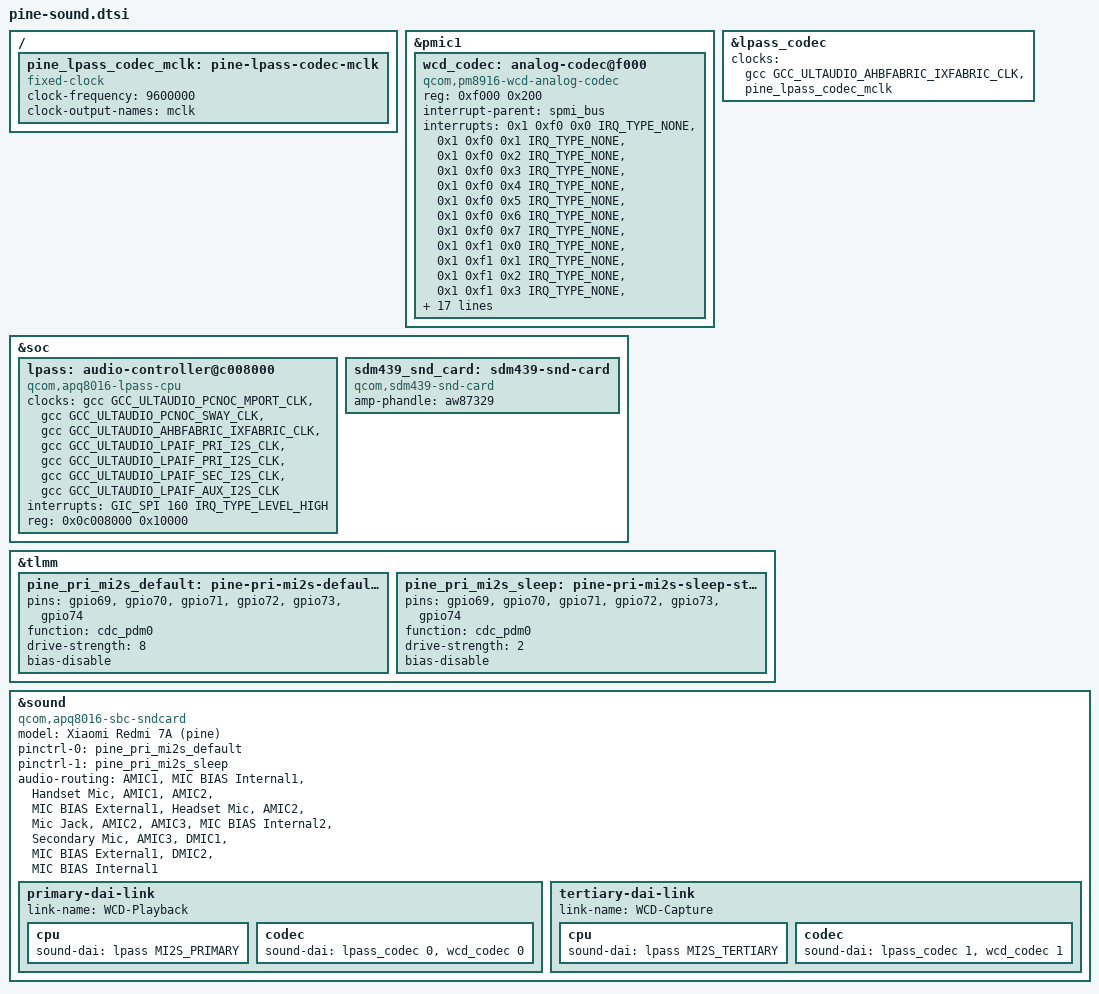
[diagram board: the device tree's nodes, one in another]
/*
 * Edited by: grayfox951 <admin@dnr.qzz.io>
 *
 * SPDX-License-Identifier: BSD-2-Clause
 */

// SPDX-License-Identifier: BSD-3-Clause
/*
 * Sound card for Xiaomi Redmi 7A (pine) / SDM439
 * =================================================
 * Kernel: msm89x7-mainline/linux @ msm89x7/7.1.3
 *
 * Machine driver:  sound/soc/qcom/apq8016_sbc.c
 *                    compatible = "qcom,apq8016-sbc-sndcard"
 *                  NO variant of it is needed. See snd/sdm439-snd-card.c.
 *
 * Codecs used:
 *                  &wcd_codec     qcom,pm8916-wcd-analog-codec  @ SPMI 0xf000
 *                                sound/soc/codecs/msm8916-wcd-analog.c
 *                                (PM8953 WCD analog half)
 *                  &lpass_codec   qcom,msm8916-wcd-digital-codec @ 0x0c0f0000
 *                                sound/soc/codecs/msm8916-wcd-digital.c
 *                                (WCD digital half + the real DMIC1/DMIC2 decoder)
 *   CPU DAI:        &lpass         qcom,apq8016-lpass-cpu
 *                                sound/soc/qcom/lpass-apq8016.c + lpass-cpu.c
 *
 * ---------------------------------------------------------------------------
 * EVERY LABEL AND PROPERTY BELOW WAS GREP-VERIFIED IN
 *   fk/arch/arm64/boot/dts/qcom/
 * unless it is inside a block explicitly marked TODO.  See snd/README.md for
 * the exact commands.
 *
 * Pine's include chain is
 *   sdm439-xiaomi-pine.dts -> sdm439.dtsi -> msm8937.dtsi
 *                          -> pm8953.dtsi, pmi632.dtsi
 * msm8937.dtsi does NOT include msm8916.dtsi.  So none of the msm8916.dtsi
 * labels (lpass:, lpass_codec:, sound:) exist for this board; the msm8937
 * equivalents are used, and &lpass is created here.
 * ---------------------------------------------------------------------------
 */

#include <dt-bindings/clock/qcom,gcc-sdm439.h>
#include <dt-bindings/interrupt-controller/arm-gic.h>
#include <dt-bindings/interrupt-controller/irq.h>
#include <dt-bindings/sound/qcom,lpass.h>

/* =========================================================================
 * 1. MCLK placeholder for lpass_codec
 *
 * msm8916-wcd-digital.c requires two clocks by name:
 *     "ahbix-clk"  and  "mclk"   (verified: get_clks(), devm_clk_get())
 * and then does clk_prepare_enable() on both, so probe FAILS without them.
 *
 *   ahbix-clk -> &gcc GCC_ULTAUDIO_AHBFABRIC_IXFABRIC_CLK
 *        Token verified in fk/include/dt-bindings/clock/qcom,gcc-sdm439.h:21
 *        Gate  verified in fk/drivers/clk/qcom/gcc-sdm439.c:3499
 *
 *   mclk      -> NO PROVIDER EXISTS.  TODO (blocking, for the clock agent).
 *        GCC_CODEC_DIGCODEC_CLK is NOT in qcom,gcc-sdm439.h (the ULTAUDIO
 *        block stops at index 158) and gcc-sdm439.c contains no digcodec
 *        gate at all.  On msm8916 this is GCC_CODEC_DIGCODEC_CLK = 159
 *        (qcom,gcc-msm8916.h:168) - one past the end of the sdm439 block.
 *        The fixed-clock below is a PLACEHOLDER so lpass_codec can probe and
 *        so the rest of the card can be brought up.  It is correct only
 *        because this board only ever runs the WCD digital codec at 9600000
 *        (apq8016_sbc.c DEFAULT_MCLK_RATE = 9600000, the only value ever
 *        passed to snd_soc_component_set_sysclk()).  If a different rate is
 *        ever needed, clk_set_rate() on a fixed clock returns -EINVAL and
 *        msm8916_wcd_digital_component_set_sysclk() propagates it.
 *
 *        REQUIRED FROM THE CLOCK AGENT: a real, gateable, settable 9.6 MHz
 *        root for the WCD CDC block, exported either as a new
 *        GCC_CODEC_DIGCODEC_CLK token in qcom,gcc-sdm439.h plus a gate in
 *        gcc-sdm439.c, or as a separate clock driver.  When it lands,
 *        replace &pine_lpass_codec_mclk below with that phandle.
 *
 *        ALSO REQUIRED: gcc-sdm439.o is NOT in drivers/clk/qcom/Makefile
 *        (only gcc-msm8917.o is, line 69).  gcc-msm8917.c matches
 *        "qcom,gcc-sdm439" at line 4179 but its table has zero ULTAUDIO
 *        gates, so even ahbix-clk above is dead until that Makefile line is
 *        added.  See snd/README.md.
 * ======================================================================= */

/ {
	pine_lpass_codec_mclk: pine-lpass-codec-mclk {
		compatible = "fixed-clock";
		#clock-cells = <0>;
		clock-frequency = <9600000>;
		clock-output-names = "mclk";
	};
};

/* =========================================================================
 * 2. WCD analog codec - PM8953 @ SPMI 0xf000, inside pmic@1
 *
 * Placed in &pmic1 (label verified: fk/arch/arm64/boot/dts/qcom/pm8953.dtsi:122).
 * pm8953.dtsi does NOT include pm8937.dtsi, so the wcd_codec node that exists
 * in pm8937.dtsi:158 is NOT visible to pine.  It is defined here instead,
 * byte-compatible with that one except for the supply names (see below).
 *
 * pmic1 already carries "#address-cells = <1>; #size-cells = <0>;" so
 * reg = <0xf000 0x200> is reg=0xf000 size=0x200.  Do not add address/size
 * cells here - pm8937.dtsi's copy does not have them either.
 *
 * ---- SUPPLY NAMES: THE ONE PLACE THIS FILE DEVIATES FROM STOCK DT -------
 *
 * stock sdm439-audio.dtsi uses the CAF names:
 *      cdc-vdd-io-supply      cdc-vdda-cp-supply
 *      cdc-vdd-pa-supply      cdc-vdd-mic-bias-supply
 *
 * sound/soc/codecs/msm8916-wcd-analog.c does NOT read any of those.  Its
 * only regulator request is (verified, exact source):
 *      static const char * const supply_names[] = {
 *              "vdd-cdc-io",
 *              "vdd-cdc-tx-rx-cx",
 *      };
 *      ret = devm_regulator_bulk_get(dev, ARRAY_SIZE(priv->supplies),
 *                                      priv->supplies);
 *      if (ret) { dev_err(...); return ret; }        <- probe dies here
 *
 * devm_regulator_bulk_get() looks up "<supply_name>-supply", i.e.
 * vdd-cdc-io-supply and vdd-cdc-tx-rx-cx-supply.  A node carrying only the
 * CAF names fails probe with -EPROBE_DEFER/-EINVAL.
 *
 * The mainline spelling is taken from the closest sibling that already works
 * in this kernel, fk/arch/arm64/boot/dts/qcom/msm8917-xiaomi-wingtech.dtsi:537
 * (msm8937 + pm8937 + the same codec driver):
 *      vdd-cdc-io-supply       = <&pm8937_l5>;
 *      vdd-cdc-tx-rx-cx-supply = <&pm8937_s4>;
 *
 * Rail mapping for pine (labels verified in sdm439-xiaomi-pine.dts):
 *      pm8953_l5  1.80 V fixed      -> vdd-cdc-io
 *      pm8953_s4  1.90 - 2.04 V    -> vdd-cdc-tx-rx-cx   (stock: cdc-vdda-cp)
 *      pm8953_s4  1.90 - 2.04 V    -> stock "cdc-vdd-pa" (no consumer below)
 *      pm8953_l13 3.05 - 3.10 V    -> vdd-micbias         (stock: cdc-vdd-mic-bias)
 *
 * The CAF-named properties are kept underneath, commented as what they are,
 * so the rail intent is recorded and so a downstream/CAF driver reading them
 * finds the right phandle.  The mainline driver ignores them.
 *
 * ---- NO clocks= ON THIS NODE -------------------------------------------
 * pm8937.dtsi:158 hangs this node off &q6afecc, whose compatible is
 * "qcom,q6afe-clocks".  No driver in this kernel binds that string, so the
 * node would sit in deferred probe forever.  It does not have to: grep shows
 * msm8916-wcd-analog.c contains no devm_clk_get()/clk_get() at all - it never
 * touches a clock, so no clocks property is needed and none is supplied.
 *
 * ---- INTERRUPT NAMES ---------------------------------------------------
 * Three of the fourteen names below differ from stock, and they are the ones
 * the driver actually looks up by name (verified in the probe function):
 *
 *   stock "mbhc_int"      -> "mbhc_switch_int"
 *   stock "but_press_det" -> "mbhc_but_press_det"
 *   stock "but_rel_det"   -> "mbhc_but_rel_det"
 *
 * because probe does:
 *      irq = platform_get_irq_byname(pdev, "mbhc_switch_int");
 *      if (irq < 0) return irq;                       <- no fallback
 *      ...
 *      if (priv->mbhc_btn_enabled) {
 *              irq = platform_get_irq_byname(pdev, "mbhc_but_press_det");
 *              if (irq < 0) return irq;
 *              irq = platform_get_irq_byname(pdev, "mbhc_but_rel_det");
 *              if (irq < 0) return irq;
 *      }
 *
 * mbhc_btn_enabled is true only if BOTH qcom,mbhc-vthreshold-low and
 * qcom,mbhc-vthreshold-high are present arrays of 5 values; those are
 * supplied below so button detection stays on and the two button IRQs are
 * required.
 * The other eleven names are only labels (platform_get_irq() is positional);
 * they are kept byte-identical to stock.
 * ======================================================================= */

&pmic1 {
	status = "okay";

	wcd_codec: analog-codec@f000 {
		compatible = "qcom,pm8916-wcd-analog-codec";
		reg = <0xf000 0x200>;
		reg-names = "pmic-codec-core";
		#sound-dai-cells = <1>;

		interrupt-parent = <&spmi_bus>;
		interrupts = <0x1 0xf0 0x0 IRQ_TYPE_NONE>,
			     <0x1 0xf0 0x1 IRQ_TYPE_NONE>,
			     <0x1 0xf0 0x2 IRQ_TYPE_NONE>,
			     <0x1 0xf0 0x3 IRQ_TYPE_NONE>,
			     <0x1 0xf0 0x4 IRQ_TYPE_NONE>,
			     <0x1 0xf0 0x5 IRQ_TYPE_NONE>,
			     <0x1 0xf0 0x6 IRQ_TYPE_NONE>,
			     <0x1 0xf0 0x7 IRQ_TYPE_NONE>,
			     <0x1 0xf1 0x0 IRQ_TYPE_NONE>,
			     <0x1 0xf1 0x1 IRQ_TYPE_NONE>,
			     <0x1 0xf1 0x2 IRQ_TYPE_NONE>,
			     <0x1 0xf1 0x3 IRQ_TYPE_NONE>,
			     <0x1 0xf1 0x4 IRQ_TYPE_NONE>,
			     <0x1 0xf1 0x5 IRQ_TYPE_NONE>;
		interrupt-names = "spk_cnp_int",
				  "spk_clip_int",
				  "spk_ocp_int",
				  "ins_rem_det1",
				  "but_rel_det",
				  "but_press_det",
				  "ins_rem_det",
				  "mbhc_switch_int",
				  "ear_ocp_int",
				  "hphr_ocp_int",
				  "hphl_ocp_det",
				  "ear_cnp_int",
				  "hphr_cnp_int",
				  "hphl_cnp_int";

		/* ---- supplies the mainline driver actually consumes ---- */
		vdd-cdc-io-supply       = <&pm8953_l5>;   /* 1.80 V  (CDC_VDD_IO)  */
		vdd-cdc-tx-rx-cx-supply = <&pm8953_s4>;   /* 1.90-2.04 V (CDC_VDDA_CP) */
		vdd-micbias-supply      = <&pm8953_l13>;  /* 3.05-3.10 V (CDC_VDD_MIC_BIAS) */

		/* ---- stock/CAF spellings: recorded, not consumed ---- */
		cdc-vdd-io-supply       = <&pm8953_l5>;
		qcom,cdc-vdd-io-voltage  = <1800000 1800000>;
		cdc-vdda-cp-supply      = <&pm8953_s4>;
		qcom,cdc-vdda-cp-voltage = <1900000 2050000>;
		cdc-vdd-pa-supply       = <&pm8953_s4>;
		qcom,cdc-vdd-pa-voltage = <1900000 2050000>;
		cdc-vdd-mic-bias-supply = <&pm8953_l13>;
		qcom,cdc-vdd-mic-bias-voltage = <3075000 3075000>;
		qcom,cdc-mclk-clk-rate  = <9600000>;

		/* ---- MBHC ----
		 * Both threshold arrays must be present and 5 entries long or
		 * mbhc_btn_enabled goes false and the button IRQs are dropped.
		 * Values are the msm8916 reference set; pine-specific threshold
		 * tuning is TODO (measure against a real headset).
		 */
		qcom,mbhc-vthreshold-low  = <75 150 237 450 500>;
		qcom,mbhc-vthreshold-high = <75 150 237 450 500>;
		qcom,micbias1-ext-cap;

		status = "okay";
	};
};

/* =========================================================================
 * 3. LPASS CPU DAI
 *
 * There is NO lpass node anywhere on pine's include chain: msm8937.dtsi has
 * none, and the only lpass node in the fork is msm8916.dtsi:2125, which pine
 * never includes.  So it is created here.
 *
 * ADDRESS - UNVERIFIED, TODO.
 * msm8916 puts LPAIF at AON_base + 0x8000, with its sound iomux at
 * AON_base + 0x2000.  sdm439's AON_base is 0x0c000000 but its internal
 * offsets clearly differ: the sound iomux is at AON+0x51000, not AON+0x2000,
 * and the WCD digital block is at AON+0xf0000, not AON+0x1c000.  So
 * "AON_base + 0x8000" is a hypothesis, not a derived fact.  It is marked as
 * such and must be confirmed before audio can work - see snd/README.md for
 * a safe read-only test procedure.  A wrong base here cannot damage the
 * device: lpass-cpu only reads its AHBIX config register and the DMAs.
 * 0x0c008000 is used below as the hypothesis.
 *
 * NO qcom,adsp PHANDLE.  asoc_qcom_lpass_cpu_platform_probe() does
 *      dsp_of_node = of_parse_phandle(pdev->dev.of_node, "qcom,adsp", 0);
 *      if (dsp_of_node) { dev_err(dev, "DSP exists and holds audio
 *      resources\n"); return -EBUSY; }
 * so a qcom,adsp phandle here is an unconditional probe failure.  pine's
 * stock DTB is stock-derived and does contain one; it is simply not written
 * here.
 *
 * CLOCKS.  clock-names is positional and must match the order the driver
 * asks for.  All seven tokens below were grep-verified in
 * fk/include/dt-bindings/clock/qcom,gcc-sdm439.h and every gate is implemented
 * in fk/drivers/clk/qcom/gcc-sdm439.c (the two tables agree 1:1).
 *
 *   name             token                                    hdr line
 *   ---------------  --------------------------------------   --------
 *   pcnoc-mport-clk  GCC_ULTAUDIO_PCNOC_MPORT_CLK            sdm439.h:17
 *   pcnoc-sway-clk   GCC_ULTAUDIO_PCNOC_SWAY_CLK             sdm439.h:18
 *   ahbix-clk        GCC_ULTAUDIO_AHBFABRIC_IXFABRIC_CLK     sdm439.h:21
 *   mi2s-bit-clk0    GCC_ULTAUDIO_LPAIF_PRI_I2S_CLK          sdm439.h:23
 *   mi2s-bit-clk1    GCC_ULTAUDIO_LPAIF_PRI_I2S_CLK          sdm439.h:23
 *   mi2s-bit-clk2    GCC_ULTAUDIO_LPAIF_SEC_I2S_CLK          sdm439.h:24
 *   mi2s-bit-clk3    GCC_ULTAUDIO_LPAIF_AUX_I2S_CLK          sdm439.h:25
 *
 * mi2s-bit-clk0 and mi2s-bit-clk1 deliberately share PRI_I2S_CLK; that is
 * what msm8916.dtsi:2136-2137 does and it is not a typo.
 *
 * mi2s-osr-clk0..3 are NOT listed: lpass-cpu.c:1224 gets them with
 * devm_clk_get_optional(), so they are genuinely optional and are left out.
 *
 * BLOCKING: none of these clocks resolve until gcc-sdm439.o is added to
 * drivers/clk/qcom/Makefile.  See the note at the top of this file.
 * ======================================================================= */

&soc {
	lpass: audio-controller@c008000 {
		status = "okay";

		/* both spellings are accepted by lpass-apq8016.c */
		compatible = "qcom,apq8016-lpass-cpu", "qcom,lpass-cpu-apq8016";

		clocks = <&gcc GCC_ULTAUDIO_PCNOC_MPORT_CLK>,
			 <&gcc GCC_ULTAUDIO_PCNOC_SWAY_CLK>,
			 <&gcc GCC_ULTAUDIO_AHBFABRIC_IXFABRIC_CLK>,
			 <&gcc GCC_ULTAUDIO_LPAIF_PRI_I2S_CLK>,
			 <&gcc GCC_ULTAUDIO_LPAIF_PRI_I2S_CLK>,
			 <&gcc GCC_ULTAUDIO_LPAIF_SEC_I2S_CLK>,
			 <&gcc GCC_ULTAUDIO_LPAIF_AUX_I2S_CLK>;
		clock-names = "pcnoc-mport-clk",
			      "pcnoc-sway-clk",
			      "ahbix-clk",
			      "mi2s-bit-clk0",
			      "mi2s-bit-clk1",
			      "mi2s-bit-clk2",
			      "mi2s-bit-clk3";

		/* TODO: verify both against the stock sdm439 device tree. */
		interrupts = <GIC_SPI 160 IRQ_TYPE_LEVEL_HIGH>;
		interrupt-names = "lpass-irq-lpaif";

		/* TODO: unverified base, see the note above. */
		reg = <0x0c008000 0x10000>;
		reg-names = "lpass-lpaif";

		#sound-dai-cells = <1>;
		#address-cells = <1>;
		#size-cells = <0>;
	};
};

/* =========================================================================
 * 4. WCD digital codec (lpass_codec)
 *
 * Label verified: fk/arch/arm64/boot/dts/qcom/msm8937.dtsi:2353,
 * reg = <0x0c0f0000 0x400>, compatible qcom,msm8916-wcd-digital-codec.
 * That is the address the stock sdm439-audio.dtsi also uses for
 * "msm_digital_codec", so it needs no guessing.
 *
 * Its stock clocks come from &q6afecc (compatible "qcom,q6afe-clocks"), for
 * which this kernel has NO driver, and the second clock is
 * &rpmcc RPM_SMD_XO_CLK_SRC - a 19.2 MHz fixed root that clk_set_rate() to
 * 9600000 (what msm8916_wcd_digital_component_set_sysclk() does) would
 * reject.  Both are replaced below.
 * ======================================================================= */

&lpass_codec {
	clocks = <&gcc GCC_ULTAUDIO_AHBFABRIC_IXFABRIC_CLK>,
		 <&pine_lpass_codec_mclk>;
	clock-names = "ahbix-clk", "mclk";

	/*
	 * TODO(clock agent): drop &pine_lpass_codec_mclk for the real
	 * GCC_CODEC_DIGCODEC_CLK-equivalent once it exists.
	 */
	#sound-dai-cells = <1>;

	status = "okay";
};

/* =========================================================================
 * 5. TLMM audio pinmux
 *
 * pine's chain has NO audio pinctrl labels of its own - msm8937.dtsi's tlmm
 * defines only blsp/cci/cam_mclk/wcss states.  So the states are declared
 * here.
 *
 * The playback (Primary MI2S) group below is copied from the in-tree
 * msm8937 board dtsi (fk/arch/arm64/boot/dts/qcom/msm8937-qdsp6.dtsi:80-100),
 * so the pin numbers gpio69..74 and the function string "cdc_pdm0" are both
 * verified for the qcom,msm8917-pinctrl node at msm8937.dtsi:820.
 *
 * TODO: confirm that pine actually bonds Primary MI2S to gpio69..74.  The
 * stock CAF DT routes it through a "msm_cdc_pinctrl_pri" node whose pinctrl-0
 * is the pair cdc_pdm_lines_act + cdc_pdm_lines_2_act, i.e. TWELVE cdc_pdm0
 * pins, not six.  Whether pine uses the 69-74 group, the 63-68 group, or
 * both has not been confirmed from any file available locally.
 *
 * TODO: the digital microphone needs gpio0/gpio1 on dmic0_clk/dmic0_data
 * (that is what msm8916.dtsi:1366-1391 does).  Those two function strings
 * are NOT verifiable from this clone - drivers/pinctrl/qcom is not present -
 * and pine.dtsi already reserves gpio0-3 with gpio-reserved-ranges = <0 4>.
 * So the DMIC pinmux is deliberately NOT written here rather than guessed.
 * Until it is, digital-mic capture registers but has no DMIC clock on the
 * pin and the two DMIC widgets will read zeros.
 * ======================================================================= */

&tlmm {
	pine_pri_mi2s_default: pine-pri-mi2s-default-state {
		pins = "gpio69", "gpio70", "gpio71",
		       "gpio72", "gpio73", "gpio74";
		function = "cdc_pdm0";
		drive-strength = <8>;
		bias-disable;
	};

	pine_pri_mi2s_sleep: pine-pri-mi2s-sleep-state {
		pins = "gpio69", "gpio70", "gpio71",
		       "gpio72", "gpio73", "gpio74";
		function = "cdc_pdm0";
		drive-strength = <2>;
		bias-disable;
	};
};

/* =========================================================================
 * 6. Speaker amplifier supervisor
 *
 * NOT a child of &sound, and not a child of &sound on purpose: see the note
 * at the top of section 7 - every non-disabled child of &sound becomes a
 * dai_link, so nothing else may live there.
 *
 * This node exists only so snd/sdm439-snd-card.c has something to bind to
 * and a phandle to the amplifier.  It is a plain platform device; it carries
 * no DAI, no codec and no AFE reference.
 *
 * The label &aw87329 belongs to the out-of-tree DT fragment for the
 * amplifier (aw87329/dts-fragment.dtsi).  That fragment is not part of this
 * kernel, so this node only resolves if it has been included too; if it has
 * not, the module simply never probes and nothing else is affected, because
 * this dtsi does not reference &aw87329 from anywhere else.
 *
 * No pinctrl and no clocks: the amplifier is switched over i2c.
 * ======================================================================= */

&soc {
	sdm439_snd_card: sdm439-snd-card {
		compatible = "qcom,sdm439-snd-card";
		status = "okay";

		/*
		 * Reference to the AW87329 i2c client.  Resolved with
		 * of_property_read_phandle() + of_find_device_by_phandle();
		 * the AW87329 node itself stays owned by its own driver.
		 */
		amp-phandle = <&aw87329>;
	};
};

/* =========================================================================
 * 7. Sound card
 *
 * Label verified: fk/arch/arm64/boot/dts/qcom/msm8937.dtsi:2340,
 *   sound: sound-card@c051000 {
 *           compatible = "qcom,msm8916-qdsp6-sndcard";
 *           reg = <0x0c051000 0x4>, <0x0c051004 0x4>,
 *                <0x0c055000 0x4>, <0x0c052000 0x4>;
 *           reg-names = "mic-iomux", "spkr-iomux", "pri-iomux", "quin-iomux";
 *           status = "disabled";
 *   };
 *
 * compatible is switched to "qcom,apq8016-sbc-sndcard".  The stock string
 * selects msm8916_qdsp6_add_ops(), which pins every link to 48 kHz/2ch/S16_LE
 * and sets card->components = "qdsp6" for the QDSP6 AFE DAIs that do not
 * exist in this kernel (no sound/soa/qcom, no sound/soc/msm).
 *
 * The four reg regions are inherited unchanged and are what the driver maps:
 *   mic-iomux   0x0c051000   REQUIRED  -> used by MI2S_TERTIARY and
 *                                     MI2S_QUATERNARY
 *   spkr-iomux  0x0c051004   REQUIRED  -> used by MI2S_PRIMARY and
 *                                     MI2S_SECONDARY
 *   pri-iomux   0x0c055000   present, unused by the driver
 *   quin-iomux  0x0c052000   optional, only read on MI2S_QUINARY, which
 *                            lpass-apq8016.c does not even register a DAI for
 *
 * qcom_snd_parse_of() walks this:
 *      num_links = of_get_available_child_count(dev->of_node);
 *      for_each_available_child_of_node(dev->of_node, np) { ...make a link... }
 * so EVERY child node that is not "disabled" becomes a dai_link.  Adding any
 * other kind of child here (a "widgets" node, an amplifier node) breaks the
 * card.  That is why the AW87329 is handled entirely outside this node.
 *
 * audio-routing - every name below was grep-verified.  Provenance:
 *   msm8916-wcd-analog.c DAPM widgets and routes; the DMIC1/DMIC2 widgets
 *   are in msm8916-wcd-digital.c (the analog codec contains zero occurrences
 *   of the string DMIC); the card widgets are the ones apq8016_sbc.c registers
 *   itself in apq8016_sbc_dapm_widgets[]:
 *       "Headphone Jack" (HP), "Mic Jack" (MIC), "Handset Mic" (MIC),
 *       "Headset Mic" (MIC), "Secondary Mic" (MIC),
 *       "Digital Mic1" (MIC), "Digital Mic2" (MIC)
 *
 * Deliberately NOT routed, and why:
 *   - "SPK_OUT".  It is a codec OUTPUT widget with no codec-side sink.  The
 *     AW87329 is an analog-input amplifier fed from SPK_OUT; modelling it as
 *     a card widget or a DAI would be wrong (it carries no I2S).  It is
 *     driven from sysfs instead - see snd/sdm439-snd-card.c.
 *   - "HPH_L"/"HPH_R"/"EAR".  No upstream msm8916 board in this kernel routes
 *     the headphone or earpiece jack; the WCD's own hphl/hphr MUX plus its
 *     MBHC state machine do it.  Inventing routes here would only add
 *     unverified paths.
 *   - the "DMIC1" -> "Digital Mic1" pair.  BOTH names exist, but
 *     msm8916-wcd-digital.c registers "Digital Mic1"/"Digital Mic2" as its own
 *     card-side MIC widgets (line 808/809) AND apq8016_sbc.c registers
 *     identically named card widgets.  That leaves TWO widgets with the same
 *     name on one card, and dapm_get_widget() returns whichever was registered
 *     first, so the route would attach to an arbitrary one of the two.
 *     "DMIC1"/"MIC BIAS External1" is used instead, which is what
 *     msm8916-acer-a1-724.dts pairs DMIC1 with.
 *
 *   - Every name here must exist, or the whole card probe fails:
 *     snd_soc_of_parse_audio_routing() -> snd_soc_dapm_add_route() ->
 *     dapm_get_widget() returns NULL for an unknown name and the error is
 *     propagated all the way out of qcom_snd_parse_of().  All twelve names
 *     were grep-verified; see snd/README.md section 3.
 *
 *   - The amplifier.  It has to stay outside this node: see section 6.
 * ======================================================================= */

&sound {
	compatible = "qcom,apq8016-sbc-sndcard";
	model = "Xiaomi Redmi 7A (pine)";
	status = "okay";

	pinctrl-names = "default", "sleep";
	pinctrl-0 = <&pine_pri_mi2s_default>;
	pinctrl-1 = <&pine_pri_mi2s_sleep>;

	audio-routing =
		/* main microphone: AMIC1 on the internal MIC_BIAS1 rail */
		"AMIC1", "MIC BIAS Internal1",
		"Handset Mic", "AMIC1",

		/* headset microphone: AMIC2 on the external MIC_BIAS2 rail */
		"AMIC2", "MIC BIAS External1",
		"Headset Mic", "AMIC2",
		"Mic Jack", "AMIC2",

		/* secondary/rear microphone: AMIC3 */
		"AMIC3", "MIC BIAS Internal2",
		"Secondary Mic", "AMIC3",

		/*
		 * Digital microphones.  DMIC1/DMIC2 are the WCD *digital*
		 * codec's ADC widgets (msm8916-wcd-digital.c:790,793); the
		 * internal chain DMIC1 -> DEC1 MUX -> CIC1 MUX -> I2S TX1 ->
		 * AIF1 Capture -> dai id 1 is already routed by that driver.
		 * TODO: confirm DMIC1/DMIC2 are actually bonded on this board
		 * before expecting non-zero data; the pinmux is missing, see
		 * section 5.
		 */
		"DMIC1", "MIC BIAS External1",
		"DMIC2", "MIC BIAS Internal1";

	/* ------------------------------------------------------------------
	 * Playback: Primary MI2S -> WCD digital AIF1 -> WCD analog.
	 *
	 * Both codecs are in the one link.  lpass_codec is the serial
	 * endpoint (its DAI 0, "AIF1 Playback"); wcd_codec is the codec that
	 * owns the jack, the headphone MUXes and set_jack.  Dropping either
	 * half breaks the link: the machine driver's apq8016_dai_init() loops
	 * for_each_rtd_codec_dais() and calls set_sysclk() and set_jack() on
	 * each, so the analog codec has to be there to get the jack.
	 * ------------------------------------------------------------------ */
	primary-dai-link {
		link-name = "WCD-Playback";
		cpu {
			sound-dai = <&lpass MI2S_PRIMARY>;
		};
		codec {
			sound-dai = <&lpass_codec 0>, <&wcd_codec 0>;
		};
	};

	/* ------------------------------------------------------------------
	 * Capture: Tertiary MI2S <- WCD digital AIF1 <- WCD analog.
	 *
	 * MI2S_TERTIARY is capture-only in lpass-apq8016.c, which is exactly
	 * right.  apq8016_dai_init() programs MIC_CTRL_TER_WS_SLAVE_SEL |
	 * MIC_CTRL_TLMM_SCLK_EN into mic-iomux for this DAI id.
	 *
	 * lpass_codec DAI 1 ("AIF1 Capture") is the endpoint that carries the
	 * audio to the SoC, and it is the only DAI on the board with an .ops
	 * that programs TX_I2S_CTL FS rate and word width.  wcd_codec DAI 1
	 * ("PDM Capture", pm8916_wcd_analog_pdm_tx) reaches ADC1/2/3 - the
	 * analog mics - and carries no DMIC logic at all.
	 * ------------------------------------------------------------------ */
	tertiary-dai-link {
		link-name = "WCD-Capture";
		cpu {
			sound-dai = <&lpass MI2S_TERTIARY>;
		};
		codec {
			sound-dai = <&lpass_codec 1>, <&wcd_codec 1>;
		};
	};
};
